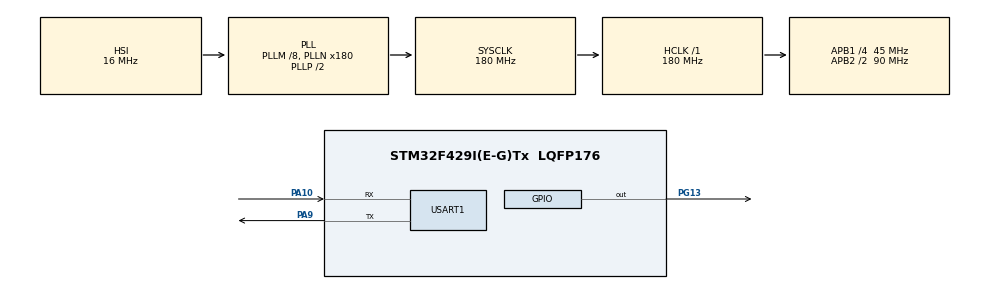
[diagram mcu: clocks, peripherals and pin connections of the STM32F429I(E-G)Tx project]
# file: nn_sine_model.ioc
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Mcu.Family=STM32F4
Mcu.Name=STM32F429I(E-G)Tx
Mcu.Package=LQFP176
NVIC.PriorityGroup=NVIC_PRIORITYGROUP_4
PA10.Mode=Asynchronous
PA10.Signal=USART1_RX
PA13.Mode=Serial_Wire
PA13.Signal=SYS_JTMS-SWDIO
PA14.Mode=Serial_Wire
PA14.Signal=SYS_JTCK-SWCLK
PA9.Mode=Asynchronous
PA9.Signal=USART1_TX
PG13.Signal=GPIO_Output
ProjectManager.HeapSize=0x800
ProjectManager.StackSize=0x800
ProjectManager.TargetToolchain=MDK-ARM V5.32
RCC.48MHZClocksFreq_Value=90000000
RCC.AHBFreq_Value=180000000
RCC.APB1CLKDivider=RCC_HCLK_DIV4
RCC.APB1Freq_Value=45000000
RCC.APB1TimFreq_Value=90000000
RCC.APB2CLKDivider=RCC_HCLK_DIV2
RCC.APB2Freq_Value=90000000
RCC.APB2TimFreq_Value=180000000
RCC.CortexFreq_Value=180000000
RCC.HCLKFreq_Value=180000000
RCC.HSE_VALUE=25000000
RCC.HSI_VALUE=16000000
RCC.LSE_VALUE=32768
RCC.PLLM=8
RCC.PLLMUL=RCC_PLL_MUL9
RCC.PLLN=180
RCC.PRESCALERUSB=RCC_USBCLKSOURCE_PLL_DIV1_5
RCC.SYSCLKFreq_VALUE=180000000
RCC.SYSCLKSource=RCC_SYSCLKSOURCE_PLLCLK
RCC.SYSCLKSourceVirtual=RCC_SYSCLKSOURCE_PLLCLK
RCC.VCOOutputFreq_Value=360000000
STMicroelectronics.X-CUBE-AI.8.1.0.ActivationBufferSizeList=1940
STMicroelectronics.X-CUBE-AI.8.1.0.ActivationBuffers=pool0
STMicroelectronics.X-CUBE-AI.8.1.0.ActivationNames=pool0
STMicroelectronics.X-CUBE-AI.8.1.0.ActivationSizes=AI_SIN_MODEL_DATA_ACTIVATION_1_SIZE
STMicroelectronics.X-CUBE-AI.8.1.0.ApplicationCcDeviceJjApplication=ApplicationTemplate
STMicroelectronics.X-CUBE-AI.8.1.0.HeapSize=0x800
STMicroelectronics.X-CUBE-AI.8.1.0.InternalRamActivationBufferMaxSize=AI_SIN_MODEL_DATA_ACTIVATIONS_SIZE
STMicroelectronics.X-CUBE-AI.8.1.0.LatestDirectoryUsed-670961788608a57325045d3f21d13c532e3c1f0d9362c4a4ce870f99c1fc5ac0=D\:\\stm
STMicroelectronics.X-CUBE-AI.8.1.0.MaximumNumberOfInputLayer=1
STMicroelectronics.X-CUBE-AI.8.1.0.MaximumNumberOfOutputLayer=1
STMicroelectronics.X-CUBE-AI.8.1.0.MaximumSizeOfInputLayer=1
STMicroelectronics.X-CUBE-AI.8.1.0.MaximumSizeOfOutputLayer=1
STMicroelectronics.X-CUBE-AI.8.1.0.ModelActualCompression-670961788608a57325045d3f21d13c532e3c1f0d9362c4a4ce870f99c1fc5ac0=0.0
STMicroelectronics.X-CUBE-AI.8.1.0.ModelCompression-670961788608a57325045d3f21d13c532e3c1f0d9362c4a4ce870f99c1fc5ac0=None
STMicroelectronics.X-CUBE-AI.8.1.0.ModelFlashOccupation-670961788608a57325045d3f21d13c532e3c1f0d9362c4a4ce870f99c1fc5ac0=11300
STMicroelectronics.X-CUBE-AI.8.1.0.ModelHashList=670961788608a57325045d3f21d13c532e3c1f0d9362c4a4ce870f99c1fc5ac0
STMicroelectronics.X-CUBE-AI.8.1.0.ModelKind-670961788608a57325045d3f21d13c532e3c1f0d9362c4a4ce870f99c1fc5ac0=TFLITE
STMicroelectronics.X-CUBE-AI.8.1.0.ModelMacc-670961788608a57325045d3f21d13c532e3c1f0d9362c4a4ce870f99c1fc5ac0=353
STMicroelectronics.X-CUBE-AI.8.1.0.ModelName-670961788608a57325045d3f21d13c532e3c1f0d9362c4a4ce870f99c1fc5ac0=sin_model
STMicroelectronics.X-CUBE-AI.8.1.0.ModelNameList=sin_model
STMicroelectronics.X-CUBE-AI.8.1.0.ModelRamOccupation-670961788608a57325045d3f21d13c532e3c1f0d9362c4a4ce870f99c1fc5ac0=1940
STMicroelectronics.X-CUBE-AI.8.1.0.ModelStructureFile-670961788608a57325045d3f21d13c532e3c1f0d9362c4a4ce870f99c1fc5ac0=/D\:/stm/sinewave_model.tflite
STMicroelectronics.X-CUBE-AI.8.1.0.ModelType-670961788608a57325045d3f21d13c532e3c1f0d9362c4a4ce870f99c1fc5ac0=STM32Cube.AI runtime
STMicroelectronics.X-CUBE-AI.8.1.0.ReadyForCodeGeneration=true
STMicroelectronics.X-CUBE-AI.8.1.0.StackSize=0x800
STMicroelectronics.X-CUBE-AI.8.1.0.WorkingBufferStartAddrList=0xFFFFFFFF
STMicroelectronics.X-CUBE-AI.8.1.0.XAaCUBEAaAICcArtificialOoIntelligenceJjCore=true
STMicroelectronics.X-CUBE-AI.8.1.0.copyWeightToRam=false
STMicroelectronics.X-CUBE-AI.8.1.0.customLayerConfigEnabled=false
STMicroelectronics.X-CUBE-AI.8.1.0.noOnnxIoTranspose=false
STMicroelectronics.X-CUBE-AI.8.1.0.useInputAllocation=true
STMicroelectronics.X-CUBE-AI.8.1.0.useOutputAllocation=true
TIM1.Prescaler=180-1
USART1.VirtualMode=VM_ASYNC
VP_CRC_VS_CRC.Mode=CRC_Activate
VP_STMicroelectronics.X-CUBE-AI_VS_ArtificialOoIntelligenceJjXAaCUBEAaAI_8.1.0.Mode=ArtificialOoIntelligenceJjXAaCUBEAaAI
VP_STMicroelectronics.X-CUBE-AI_VS_DeviceJjApplication_8.1.0.Mode=DeviceJjApplication
VP_TIM1_VS_ClockSourceINT.Mode=Internal
board=custom

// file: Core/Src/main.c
/* USER CODE BEGIN Header */
/**
  ******************************************************************************
  * @file           : main.c
  * @brief          : Main program body
  ******************************************************************************
  * @attention
  *
  * Copyright (c) 2024 STMicroelectronics.
  * All rights reserved.
  *
  * This software is licensed under terms that can be found in the LICENSE file
  * in the root directory of this software component.
  * If no LICENSE file comes with this software, it is provided AS-IS.
  *
  ******************************************************************************
  */
/* USER CODE END Header */
#include "main.h"
#include "app_x-cube-ai.h"

/* USER CODE BEGIN Includes */
#include <stdlib.h>
#include <stdio.h>
#include <string.h>
#include "sin_model.h"
#include "sin_model_data.h"
/* USER CODE END Includes */

CRC_HandleTypeDef hcrc;

TIM_HandleTypeDef htim1;

UART_HandleTypeDef huart1;

void SystemClock_Config(void);
static void MX_GPIO_Init(void);
static void MX_CRC_Init(void);
static void MX_TIM1_Init(void);
static void MX_USART1_UART_Init(void);

/* USER CODE BEGIN 0 */
//AI_ALIGNED(4) ai_u8 activations[AI_SIN_MODEL_DATA_ACTIVATIONS_SIZE];
//AI_ALIGNED(4) ai_u8 in_data[AI_SIN_MODEL_IN_1_SIZE_BYTES];
//AI_ALIGNED(4) ai_u8 out_data[AI_SIN_MODEL_OUT_1_SIZE_BYTES];
ai_u8 activations[AI_SIN_MODEL_DATA_ACTIVATIONS_SIZE];
ai_u8 in_data[AI_SIN_MODEL_IN_1_SIZE_BYTES]; // khai bao 1 du lieu dau vao float chua trong mang 4 byte
ai_u8 out_data[AI_SIN_MODEL_OUT_1_SIZE_BYTES]; // khai bao 1 du lieu dau ra float chua trong mang 4 byte

/* AI buffer IO handlers */
ai_buffer *ai_input; // khai bao du lieu dau vao chuan cua mang neral
ai_buffer *ai_output; // khai bao du lieu dau ra chuan cua mang neral
float out_infer;
float count =0;
uint32_t time_start=0;
/* USER CODE END 0 */

int main(void)
{
  /* USER CODE BEGIN 1 */
	ai_handle sin_model = AI_HANDLE_NULL;  // khai bao model
	ai_error err;														// khai bao bien error
	ai_network_report report;			 	// khai bao bien report
  /* USER CODE END 1 */

  /* MCU Configuration--------------------------------------------------------*/

  /* Reset of all peripherals, Initializes the Flash interface and the Systick. */
  HAL_Init();

  /* Configure the system clock */
  SystemClock_Config();

  /* Initialize all configured peripherals */
  MX_GPIO_Init();
  MX_CRC_Init();
  MX_TIM1_Init();
  MX_USART1_UART_Init();
  //MX_X_CUBE_AI_Init();
  /* USER CODE BEGIN 2 */
	//----Khoi tao model----------------
	  const ai_handle acts[] = { activations };
    err = ai_sin_model_create_and_init(&sin_model, acts, NULL);  // tao model

    if (err.type != AI_ERROR_NONE) {
        printf("ai init_and_create error\n");
        return -1;
    }
		if (ai_sin_model_get_report(sin_model, &report) != true) {
        printf("ai get report error\n");
        return -1;
    }
//------ In thong tin model ---------------
		printf("Model name      : %s\n", report.model_name);
    printf("Model signature : %s\n", report.model_signature);

    ai_input = &report.inputs[0];
    ai_output = &report.outputs[0];
    printf("input[0] : (%d, %d, %d)\n", AI_BUFFER_SHAPE_ELEM(ai_input, AI_SHAPE_HEIGHT),
                                        AI_BUFFER_SHAPE_ELEM(ai_input, AI_SHAPE_WIDTH),
                                        AI_BUFFER_SHAPE_ELEM(ai_input, AI_SHAPE_CHANNEL));
    printf("output[0] : (%d, %d, %d)\n", AI_BUFFER_SHAPE_ELEM(ai_output, AI_SHAPE_HEIGHT),
                                         AI_BUFFER_SHAPE_ELEM(ai_output, AI_SHAPE_WIDTH),
                                         AI_BUFFER_SHAPE_ELEM(ai_output, AI_SHAPE_CHANNEL));

//-- Doc cau truc data input, data output cua mang NN
		ai_i32 n_batch;
		ai_input = ai_sin_model_inputs_get(sin_model, NULL);
    ai_output = ai_sin_model_outputs_get(sin_model, NULL);

//---- gan data vao mang NN
		ai_input[0].data = AI_HANDLE_PTR(in_data);
    ai_output[0].data = AI_HANDLE_PTR(out_data);

//--- Start timer/counter
		HAL_TIM_Base_Start(&htim1);
  /* USER CODE END 2 */

  /* Infinite loop */
  while (1)
  {

  //MX_X_CUBE_AI_Process();
    /* USER CODE BEGIN 3 */
		//-----Tao du lieu dau vao kieu float 4bytes
    for (uint32_t i = 0; i < AI_SIN_MODEL_IN_1_SIZE; i++)
    {
      ((ai_float *)in_data)[i] = (ai_float)(count/100);
    }
//---Get current timestamp
    time_start = htim1.Instance->CNT;
//----- Run model
		n_batch = ai_sin_model_run(sin_model, &ai_input[0], &ai_output[0]);
	  if (n_batch != 1) {
        err = ai_sin_model_get_error(sin_model);
        printf("ai run error %d, %d\n", err.type, err.code);
      return -1;
    }
		out_infer = ((float *)out_data)[0]; // chuyen 4bytes int -> float
//    for (int i = 0; i < AI_SIN_MODEL_OUT_1_SIZE; i++) {
//        printf("%d", out_data[i]);
//    }
		printf("\nInference times:%d",htim1.Instance->CNT - time_start);
    printf("\nInference output:%f",out_infer);
//---------------------------------------
		//HAL_UART_Transmit(&huart2, M, strlen(M), 1000);
		HAL_GPIO_TogglePin(GPIOG, GPIO_PIN_13);
		HAL_Delay(200);
		count++;
		if(count>628)count=0;
  }
  /* USER CODE END 3 */
}

void SystemClock_Config(void)
{
  RCC_OscInitTypeDef RCC_OscInitStruct = {0};
  RCC_ClkInitTypeDef RCC_ClkInitStruct = {0};

  /** Configure the main internal regulator output voltage
  */
  __HAL_RCC_PWR_CLK_ENABLE();
  __HAL_PWR_VOLTAGESCALING_CONFIG(PWR_REGULATOR_VOLTAGE_SCALE1);

  /** Initializes the RCC Oscillators according to the specified parameters
  * in the RCC_OscInitTypeDef structure.
  */
  RCC_OscInitStruct.OscillatorType = RCC_OSCILLATORTYPE_HSI;
  RCC_OscInitStruct.HSIState = RCC_HSI_ON;
  RCC_OscInitStruct.HSICalibrationValue = RCC_HSICALIBRATION_DEFAULT;
  RCC_OscInitStruct.PLL.PLLState = RCC_PLL_ON;
  RCC_OscInitStruct.PLL.PLLSource = RCC_PLLSOURCE_HSI;
  RCC_OscInitStruct.PLL.PLLM = 8;
  RCC_OscInitStruct.PLL.PLLN = 180;
  RCC_OscInitStruct.PLL.PLLP = RCC_PLLP_DIV2;
  RCC_OscInitStruct.PLL.PLLQ = 4;
  if (HAL_RCC_OscConfig(&RCC_OscInitStruct) != HAL_OK)
  {
    Error_Handler();
  }

  /** Activate the Over-Drive mode
  */
  if (HAL_PWREx_EnableOverDrive() != HAL_OK)
  {
    Error_Handler();
  }

  /** Initializes the CPU, AHB and APB buses clocks
  */
  RCC_ClkInitStruct.ClockType = RCC_CLOCKTYPE_HCLK|RCC_CLOCKTYPE_SYSCLK
                              |RCC_CLOCKTYPE_PCLK1|RCC_CLOCKTYPE_PCLK2;
  RCC_ClkInitStruct.SYSCLKSource = RCC_SYSCLKSOURCE_PLLCLK;
  RCC_ClkInitStruct.AHBCLKDivider = RCC_SYSCLK_DIV1;
  RCC_ClkInitStruct.APB1CLKDivider = RCC_HCLK_DIV4;
  RCC_ClkInitStruct.APB2CLKDivider = RCC_HCLK_DIV2;

  if (HAL_RCC_ClockConfig(&RCC_ClkInitStruct, FLASH_LATENCY_5) != HAL_OK)
  {
    Error_Handler();
  }
}

static void MX_CRC_Init(void)
{

  hcrc.Instance = CRC;
  if (HAL_CRC_Init(&hcrc) != HAL_OK)
  {
    Error_Handler();
  }

}

static void MX_TIM1_Init(void)
{

  TIM_ClockConfigTypeDef sClockSourceConfig = {0};
  TIM_MasterConfigTypeDef sMasterConfig = {0};

  htim1.Instance = TIM1;
  htim1.Init.Prescaler = 180-1;
  htim1.Init.CounterMode = TIM_COUNTERMODE_UP;
  htim1.Init.Period = 65535;
  htim1.Init.ClockDivision = TIM_CLOCKDIVISION_DIV1;
  htim1.Init.RepetitionCounter = 0;
  htim1.Init.AutoReloadPreload = TIM_AUTORELOAD_PRELOAD_DISABLE;
  if (HAL_TIM_Base_Init(&htim1) != HAL_OK)
  {
    Error_Handler();
  }
  sClockSourceConfig.ClockSource = TIM_CLOCKSOURCE_INTERNAL;
  if (HAL_TIM_ConfigClockSource(&htim1, &sClockSourceConfig) != HAL_OK)
  {
    Error_Handler();
  }
  sMasterConfig.MasterOutputTrigger = TIM_TRGO_RESET;
  sMasterConfig.MasterSlaveMode = TIM_MASTERSLAVEMODE_DISABLE;
  if (HAL_TIMEx_MasterConfigSynchronization(&htim1, &sMasterConfig) != HAL_OK)
  {
    Error_Handler();
  }

}

static void MX_USART1_UART_Init(void)
{

  huart1.Instance = USART1;
  huart1.Init.BaudRate = 115200;
  huart1.Init.WordLength = UART_WORDLENGTH_8B;
  huart1.Init.StopBits = UART_STOPBITS_1;
  huart1.Init.Parity = UART_PARITY_NONE;
  huart1.Init.Mode = UART_MODE_TX_RX;
  huart1.Init.HwFlowCtl = UART_HWCONTROL_NONE;
  huart1.Init.OverSampling = UART_OVERSAMPLING_16;
  if (HAL_UART_Init(&huart1) != HAL_OK)
  {
    Error_Handler();
  }

}

static void MX_GPIO_Init(void)
{
  GPIO_InitTypeDef GPIO_InitStruct = {0};

  /* GPIO Ports Clock Enable */
  __HAL_RCC_GPIOA_CLK_ENABLE();
  __HAL_RCC_GPIOG_CLK_ENABLE();

  /*Configure GPIO pin Output Level */
  HAL_GPIO_WritePin(GPIOG, GPIO_PIN_13, GPIO_PIN_RESET);

  /*Configure GPIO pin : PG13 */
  GPIO_InitStruct.Pin = GPIO_PIN_13;
  GPIO_InitStruct.Mode = GPIO_MODE_OUTPUT_PP;
  GPIO_InitStruct.Pull = GPIO_NOPULL;
  GPIO_InitStruct.Speed = GPIO_SPEED_FREQ_LOW;
  HAL_GPIO_Init(GPIOG, &GPIO_InitStruct);

}

void Error_Handler(void)
{
  __disable_irq();
  while (1)
  {
  }
}

/* USER CODE BEGIN 7 */
#ifdef __GNUC__
  /* With GCC/RAISONANCE, small printf (option LD Linker->Libraries->Small printf
     set to 'Yes') calls __io_putchar() */
  #define PUTCHAR_PROTOTYPE int __io_putchar(int ch)
#else
  #define PUTCHAR_PROTOTYPE int fputc(int ch, FILE *f)
#endif /* __GNUC__ */
/**
  * @brief  Retargets the C library printf function to the USART.
  * @param  None
  * @retval None
  */
PUTCHAR_PROTOTYPE
{
  /* Place your implementation of fputc here */
  /* e.g. write a character to the EVAL_COM1 and Loop until the end of transmission */
  HAL_UART_Transmit(&huart1, (uint8_t *)&ch, 1, 0xFFFF);

  return ch;
}
/* USER CODE END 7 */
